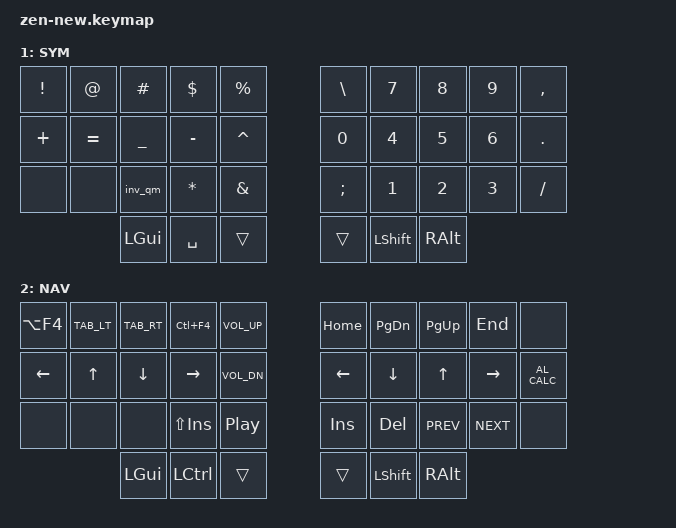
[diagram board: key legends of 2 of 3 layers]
#include <behaviors.dtsi>
#include <dt-bindings/zmk/keys.h>
#include <dt-bindings/zmk/bt.h>
#include <dt-bindings/zmk/outputs.h>
#ifdef EXTERNAL_POWER
#    include <dt-bindings/zmk/ext_power.h>
#endif

// Layer aliases
#define DEF 0
#define CLM 1
#define GME 2
#define SYM 3
#define NAV 4
#define FUN 5


#define THREE_THUMBS

// Desktop and tab navigation shortcuts
#define D_LT   LC(LG(LEFT))
#define D_RT   LC(LG(RIGHT))
#define TAB_RT LC(TAB)
#define TAB_LT LC(LS(TAB))

#include "combos.dtsi"

&mt {
    flavor = "hold-preferred";
    tapping-term-ms = <150>;
};

&lt {
    flavor = "balanced";
    tapping-term-ms = <150>;
};

&caps_word {
    continue-list = <UNDERSCORE MINUS BSPC DEL N1 N2 N3 N4 N5 N6 N7 N8 N9 N0>;
};

/ {
    behaviors {
        am: alpha_mods {
            compatible = "zmk,behavior-hold-tap";
            label = "ALPHA_MT";
            #binding-cells = <2>;
            tapping-term-ms = <200>;
            quick-tap-ms = <150>;
            flavor = "tap-preferred";
            bindings = <&kp>, <&kp>;
        };
        as: alpha_shift {
            compatible = "zmk,behavior-hold-tap";
            label = "ALPHA_SFT";
            #binding-cells = <2>;
            tapping-term-ms = <200>;
            quick-tap-ms = <150>;
            flavor = "tap-preferred";
            bindings = <&kp>, <&kp>;
        };

        // Easy alt-tab with alt+backspace thumb using mod-morphs
        bstab: backspace_tab {
            compatible = "zmk,behavior-mod-morph";
            label = "BSPC_TAB";
            #binding-cells = <0>;
            bindings = <&kp BSPC>, <&kp TAB>;
            mods = <MOD_LALT>;
        };
        lt_bspc: layer_tap_backspace_tab {
            compatible = "zmk,behavior-hold-tap";
            label = "LT_BT";
            #binding-cells = <2>;
            tapping-term-ms = <150>;
            flavor = "balanced";
            bindings = <&mo>, <&bstab>;
        };
    };

    cond_layers {
        compatible = "zmk,conditional-layers";
        // Define FUN layer as tri-state
        func_tristate {
            if-layers = <NAV SYM>;
            then-layer = <FUN>;
        };
    };

    macros {
        ZMK_MACRO(inv_qm,
            wait-ms = <10>;
            tap-ms = <10>;
            bindings
                = <&macro_press &kp LALT>
                , <&macro_tap &kp KP_N1 &kp KP_N6 &kp KP_N8>
                , <&macro_release &kp LALT>;
        )
    };

    keymap {
        compatible = "zmk,keymap";

        default_layer {
            label = "DEF";
            bindings = <
// ╭─────────────┬─────────────┬─────────────┬─────────────┬─────────────┬─────────────╮   ╭─────────────┬─────────────┬─────────────┬─────────────┬─────────────┬─────────────╮
     &kp ESC       &kp Q         &kp W         &kp E         &kp R         &kp T             &kp Y         &kp U         &kp I         &kp O         &kp P         &kp BSPC
// ├─────────────┼─────────────┼─────────────┼─────────────┼─────────────┼─────────────┤   ├─────────────┼─────────────┼─────────────┼─────────────┼─────────────┼─────────────┤
     &kp LSHIFT     &am LGUI A   &am LALT S    &am LCTRL D  &as LSHIFT F   &kp G             &kp H         &as RSHIFT J  &am RCTRL K    &am RALT L   &am RGUI SQT  &kp SQT
// ├─────────────┼─────────────┼─────────────┼─────────────┼─────────────┼─────────────┤   ├─────────────┼─────────────┼─────────────┼─────────────┼─────────────┼─────────────┤
     &kp TILDE     &kp Z         &kp X         &kp C         &kp V         &kp B             &kp N         &kp M         &kp COMMA     &kp DOT       &kp SLASH     &kp PIPE
// ╰─────────────┴─────────────┴─────────────┴─────────────┼─────────────┼─────────────┤   ├─────────────┼─────────────┼─────────────┼─────────────┴─────────────┴─────────────╯
#ifdef THREE_THUMBS
                                              &mt LGUI TAB  &mt LCTRL ESC  &lt NAV RET      &lt SYM SPACE &mt RSHFT TAB &mt RALT DEL
#else
                                                            &mt LCTRL ESC  &lt NAV RET      &lt SYM SPACE &mt RSHFT TAB
#endif
//                                                         ╰─────────────┴─────────────╯   ╰─────────────┴─────────────╯
            >;
        };

        symbol_layer {
            label = "SYM";
            bindings = <
// ╭─────────────┬─────────────┬─────────────┬─────────────┬─────────────╮   ╭─────────────┬─────────────┬─────────────┬─────────────┬─────────────╮
     &kp EXCL      &kp AT        &kp HASH      &kp DLLR      &kp PRCNT         &kp BSLH      &kp N7        &kp N8        &kp N9        &kp COMMA
// ├─────────────┼─────────────┼─────────────┼─────────────┼─────────────┤   ├─────────────┼─────────────┼─────────────┼─────────────┼─────────────┤
     &kp PLUS      &kp EQUAL     &kp UNDER     &kp MINUS     &kp CARET         &kp N0        &kp N4        &kp N5        &kp N6        &kp DOT
// ├─────────────┼─────────────┼─────────────┼─────────────┼─────────────┤   ├─────────────┼─────────────┼─────────────┼─────────────┼─────────────┤
     &none         &none         &inv_qm       &kp STAR      &kp AMPS          &kp SEMI      &kp N1        &kp N2        &kp N3        &kp SLASH
// ╰─────────────┴─────────────┴─────────────┼─────────────┼─────────────┤   ├─────────────┼─────────────┼─────────────┴─────────────┴─────────────╯
#ifdef THREE_THUMBS
                                 &kp LGUI      &kp SPACE     &trans            &trans        &kp LSHFT     &kp RALT
#else
                                               &kp SPACE     &trans            &trans        &kp LSHFT
#endif
//                                           ╰─────────────┴─────────────╯   ╰─────────────┴─────────────╯
            >;
        };


        nav_layer {
            label = "NAV";
            bindings = <
// ╭─────────────┬─────────────┬─────────────┬─────────────┬─────────────╮   ╭─────────────┬─────────────┬─────────────┬─────────────┬─────────────╮
     &kp LA(F4)    &kp TAB_LT    &kp TAB_RT    &kp LC(F4)    &kp C_VOL_UP      &kp HOME      &kp PG_DN     &kp PG_UP     &kp END       &none
// ├─────────────┼─────────────┼─────────────┼─────────────┼─────────────┤   ├─────────────┼─────────────┼─────────────┼─────────────┼─────────────┤
     &kp LEFT       &kp UP       &kp DOWN     &kp RIGHT     &kp C_VOL_DN      &kp LEFT      &kp DOWN      &kp UP        &kp RIGHT     &kp C_AL_CALC
// ├─────────────┼─────────────┼─────────────┼─────────────┼─────────────┤   ├─────────────┼─────────────┼─────────────┼─────────────┼─────────────┤
     &none         &none         &none         &kp LS(INS)   &kp C_PP          &kp INS       &kp DEL       &kp C_PREV    &kp C_NEXT    &none
// ╰─────────────┴─────────────┴─────────────┼─────────────┼─────────────┤   ├─────────────┼─────────────┼─────────────┴─────────────┴─────────────╯
#ifdef THREE_THUMBS
                                 &kp LGUI      &kp LCTRL     &trans            &trans        &kp LSHFT     &kp RALT
#else
                                               &kp LCTRL     &trans            &trans        &kp LSHFT
#endif
//                                           ╰─────────────┴─────────────╯   ╰─────────────┴─────────────╯
            >;
        };
    };
};
